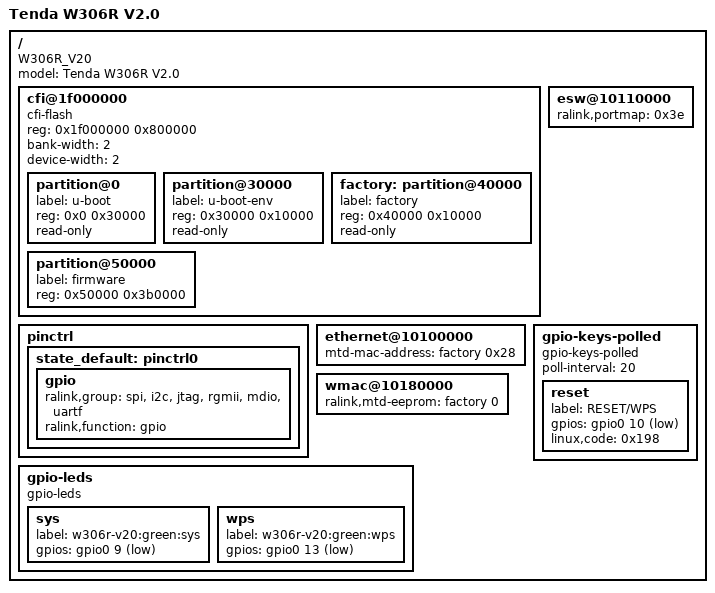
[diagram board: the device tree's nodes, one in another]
/dts-v1/;

/include/ "rt3050.dtsi"

/ {
	compatible = "W306R_V20", "ralink,rt3052-soc";
	model = "Tenda W306R V2.0";

	cfi@1f000000 {
		compatible = "cfi-flash";
		reg = <0x1f000000 0x800000>;

		bank-width = <2>;
		device-width = <2>;
		#address-cells = <1>;
		#size-cells = <1>;

		partition@0 {
			label = "u-boot";
			reg = <0x0 0x30000>;
			read-only;
		};

		partition@30000 {
			label = "u-boot-env";
			reg = <0x30000 0x10000>;
			read-only;
		};

		factory: partition@40000 {
			label = "factory";
			reg = <0x40000 0x10000>;
			read-only;
		};

		partition@50000 {
			label = "firmware";
			reg = <0x50000 0x3b0000>;
		};
	};

	pinctrl {
		state_default: pinctrl0 {
			gpio {
				ralink,group = "spi", "i2c", "jtag", "rgmii", "mdio", "uartf";
				ralink,function = "gpio";
			};
		};
	};

	ethernet@10100000 {
		mtd-mac-address = <&factory 0x28>;
	};

	esw@10110000 {
		ralink,portmap = <0x3e>;
	};

	wmac@10180000 {
		ralink,mtd-eeprom = <&factory 0>;
	};

	gpio-leds {
		compatible = "gpio-leds";
		sys {
			label = "w306r-v20:green:sys";
			gpios = <&gpio0 9 1>;
		};
		wps {
			label = "w306r-v20:green:wps";
			gpios = <&gpio0 13 1>;
		};
	};

	gpio-keys-polled {
		compatible = "gpio-keys-polled";
		#address-cells = <1>;
		#size-cells = <0>;
		poll-interval = <20>;
		reset {
			label = "RESET/WPS";
			gpios = <&gpio0 10 1>;
			linux,code = <0x198>;
		};
	};
};
